# SKEAZN642 register map
Vendor: Freescale Semiconductor, Inc.; Series: Kinetis_EA; File version: 1.6
CPU: CM0PLUS r0p0, little endian, no MPU, no FPU, VTOR, 2 interrupt priority bits
Registers are 32-bit, read-write, reset 0x0 unless marked. A register's access mark holds for its fields unless they carry their own. Offsets are from the block's base; [hi:lo] are bit positions; 'fields as' and 'values as' point back to an identical list.

## FTMRH — Flash Memory
Base 0x40020000; register names take the prefix FTMRH_
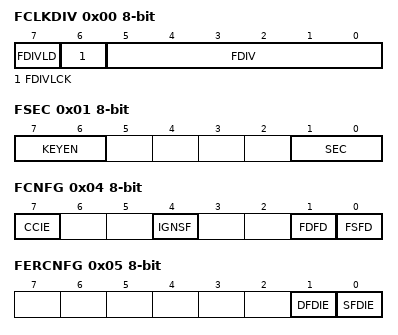
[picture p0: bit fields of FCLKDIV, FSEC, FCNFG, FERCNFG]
0x00 FCLKDIV 8-bit — Flash Clock Divider Register
  [7] FDIVLD ro — Clock Divider Loaded
    0=FCLKDIV register has not been written since the last reset; 1=FCLKDIV register has been written since the last reset
  [6] FDIVLCK — Clock Divider Locked
    0=FDIV field is open for writing; 1=FDIV value is locked and cannot be changed. After the lock bit is set high, only reset can clear this bit and restore writability to the FDIV field in user mode.
  [5:0] FDIV — Clock Divider Bits
0x01 FSEC 8-bit ro reset not defined — Flash Security Register
  [7:6] KEYEN — Backdoor Key Security Enable Bits
    0=Disabled; 1=Disabled; 2=Enabled; 3=Disabled
  [1:0] SEC — Flash Security Bits
    0=Secured; 1=Secured; 2=Unsecured; 3=Secured
0x02 FCCOBIX 8-bit — Flash CCOB Index Register
  [2:0] CCOBIX — Common Command Register Index
0x04 FCNFG 8-bit — Flash Configuration Register
  [7] CCIE — Command Complete Interrupt Enable
    0=Command complete interrupt is disabled; 1=An interrupt will be requested whenever the CCIF flag in the FSTAT register is set
  [4] IGNSF — Ignore Single Bit Fault
    0=All single-bit faults detected during array reads are reported; 1=Single-bit faults detected during array reads are not reported and the single bit fault interrupt will not be generated
  [1] FDFD — Force Double Bit Fault Detect
    0=Flash array read operations will set the FERSTAT[DFDIF] flag only if a double bit fault is detected; 1=Any flash array read operation will force the FERSTAT[DFDIF] flag to be set and an interrupt will be generated as long as FERCNFG[DFDIE] is set
  [0] FSFD — Force Single Bit Fault Detect
    0=Flash array read operations will set the SFDIF flag in the FERSTAT register only if a single bit fault is detected; 1=Flash array read operation will force the SFDIF flag in the FERSTAT register to be set and an interrupt will be generated as long as FERCNFG[SFDIE] is set
0x05 FERCNFG 8-bit — Flash Error Configuration Register
  [1] DFDIE — Double Bit Fault Detect Interrupt Enable
    0=DFDIF interrupt is disabled; 1=An interrupt will be requested whenever the DFDIF flag is set
  [0] SFDIE — Single Bit Fault Detect Interrupt Enable
    0=SFDIF interrupt is disabled whenever the SFDIF flag is set; 1=An interrupt will be requested whenever the SFDIF flag is set
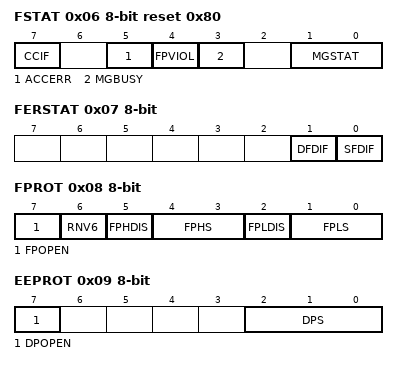
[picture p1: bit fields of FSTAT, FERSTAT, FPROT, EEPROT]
0x06 FSTAT 8-bit reset 0x80 — Flash Status Register
  [7] CCIF — Command Complete Interrupt Flag
    0=Flash command is in progress; 1=Flash command has completed
  [5] ACCERR — Flash Access Error Flag
    0=No access error is detected; 1=Access error is detected
  [4] FPVIOL — Flash Protection Violation Flag
    0=No protection violation is detected; 1=Protection violation is detected
  [3] MGBUSY ro — Memory Controller Busy Flag
    0=Memory controller is idle; 1=Memory controller is busy executing a flash command (CCIF = 0)
  [1:0] MGSTAT ro — Memory Controller Command Completion Status Flag
0x07 FERSTAT 8-bit — Flash Error Status Register
  [1] DFDIF — Double Bit Fault Detect Interrupt Flag
    0=No double bit fault detected; 1=Double bit fault detected or a flash array read operation returning invalid data was attempted while command running
  [0] SFDIF — Single Bit Fault Detect Interrupt Flag
    0=No single bit fault detected; 1=Single bit fault detected and corrected or a flash array read operation returning invalid data was attempted while command running
0x08 FPROT 8-bit reset not defined — Flash Protection Register
  [7] FPOPEN — Flash Protection Operation Enable
    0=When FPOPEN is clear, the FPHDIS and FPLDIS fields define unprotected address ranges as specified by the corresponding FPHS and FPLS fields; 1=When FPOPEN is set, the FPHDIS and FPLDIS fields enable protection for the address range specified by the corresponding FPHS and FPLS fields
  [6] RNV6 ro — Reserved Nonvolatile Bit
  [5] FPHDIS — Flash Protection Higher Address Range Disable
    0=Protection/Unprotection enabled; 1=Protection/Unprotection disabled
  [4:3] FPHS — Flash Protection Higher Address Size
  [2] FPLDIS — Flash Protection Lower Address Range Disable
    values as FPHDIS
  [1:0] FPLS — Flash Protection Lower Address Size
0x09 EEPROT 8-bit reset not defined — EEPROM Protection Register
  [7] DPOPEN — EEPROM Protection Control
    0=Enables EEPROM memory protection from program and erase with protected address range defined by DPS bits; 1=Disables EEPROM memory protection from program and erase
  [2:0] DPS — EEPROM Protection Size
0x0A FCCOBHI 8-bit — Flash Common Command Object Register:High
  [7:0] CCOB — Common Command Object Bit 15:8
0x0B FCCOBLO 8-bit — Flash Common Command Object Register: Low
  [7:0] CCOB — Common Command Object Bit 7:0
0x0C FOPT 8-bit ro reset not defined — Flash Option Register
  [7:0] NV — Nonvolatile Bits

## Notices in the file
Redistribution and use in source and binary forms, with or without modification,
are permitted provided that the following conditions are met:
o Redistributions of source code must retain the above copyright notice, this list
of conditions and the following disclaimer.
o Redistributions in binary form must reproduce the above copyright notice, this
list of conditions and the following disclaimer in the documentation and/or
other materials provided with the distribution.
o Neither the name of Freescale Semiconductor, Inc. nor the names of its
contributors may be used to endorse or promote products derived from this
software without specific prior written permission.
THIS SOFTWARE IS PROVIDED BY THE COPYRIGHT HOLDERS AND CONTRIBUTORS "AS IS" AND
ANY EXPRESS OR IMPLIED WARRANTIES, INCLUDING, BUT NOT LIMITED TO, THE IMPLIED
WARRANTIES OF MERCHANTABILITY AND FITNESS FOR A PARTICULAR PURPOSE ARE
DISCLAIMED. IN NO EVENT SHALL THE COPYRIGHT HOLDER OR CONTRIBUTORS BE LIABLE FOR
ANY DIRECT, INDIRECT, INCIDENTAL, SPECIAL, EXEMPLARY, OR CONSEQUENTIAL DAMAGES
(INCLUDING, BUT NOT LIMITED TO, PROCUREMENT OF SUBSTITUTE GOODS OR SERVICES;
LOSS OF USE, DATA, OR PROFITS; OR BUSINESS INTERRUPTION) HOWEVER CAUSED AND ON
ANY THEORY OF LIABILITY, WHETHER IN CONTRACT, STRICT LIABILITY, OR TORT
(INCLUDING NEGLIGENCE OR OTHERWISE) ARISING IN ANY WAY OUT OF THE USE OF THIS
SOFTWARE, EVEN IF ADVISED OF THE POSSIBILITY OF SUCH DAMAGE.
